# XMC4300 register map
Vendor: Infineon; File version: 0.5.1 (Superset device XMC4800)
CPU: CM4 r2p0, little endian, MPU, FPU, 6 interrupt priority bits
Registers are 32-bit, read-write, reset 0x0 unless marked. A register's access mark holds for its fields unless they carry their own. Offsets are from the block's base; [hi:lo] are bit positions; {n}, {i} and the like mark numbered series; 'fields as' and 'values as' point back to an identical list.

## FLASH0 — Flash Memory Controller
Base 0x58001000
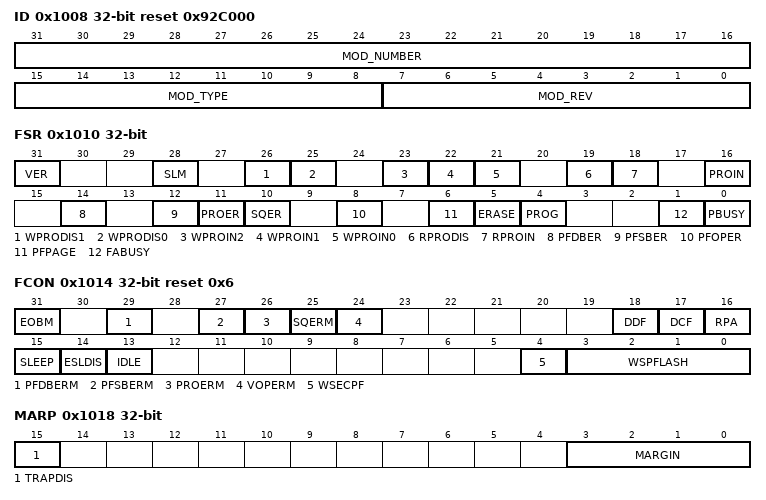
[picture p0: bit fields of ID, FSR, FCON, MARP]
0x1008 ID ro reset 0x92C000 (reset mask 0xFFFFFF00) — Flash Module Identification Register
  [31:16] MOD_NUMBER — Module Number Value
  [15:8] MOD_TYPE — Module Type
  [7:0] MOD_REV — Module Revision Number
0x1010 FSR ro — Flash Status Register
  [31] VER — Verify Error
    0=The page is correctly programmed or the sector correctly erased. All programmed or erased bits have full expected quality.; 1=A program verify error or an erase verify error has been detected. Full quality (retention time) of all programmed ("1") or erased ("0") bits cannot be guaranteed.
  [28] SLM — Flash Sleep Mode
    0=Flash not in sleep mode; 1=Flash is in sleep or shut down mode
  [26] WPRODIS1 — Sector Write Protection Disabled for User 1
    0=All protected sectors of user 1 are locked if write protection is installed; 1=All write-protected sectors of user 1 are temporarily unlocked, if not coincidently locked by user 0 or user 2 or via read protection
  [25] WPRODIS0 — Sector Write Protection Disabled for User 0
    0=All protected sectors of user 0 are locked if write protection is installed; 1=All write-protected sectors of user 0 are temporarily unlocked, if not coincidently locked by user 2 or via read protection
  [23] WPROIN2 — Sector OTP Protection Installed for User 2
    0=No OTP write protection installed for user 2; 1=Sector OTP write protection with ROM functionality is configured and correctly confirmed in the UCB2. The protection is locked for ever.
  [22] WPROIN1 — Sector Write Protection Installed for User 1
    0=No write protection installed for user 1; 1=Sector write protection for user 1 is configured and correctly confirmed in the User Configuration Block 1
  [21] WPROIN0 — Sector Write Protection Installed for User 0
    0=No write protection installed for user 0; 1=Sector write protection for user 0 is configured and correctly confirmed in the User Configuration Block 0
  [19] RPRODIS — Read Protection Disable State
    0=Read protection (if installed) is not disabled; 1=Read and global write protection is temporarily disabled
  [18] RPROIN — Read Protection Installed
    0=No read protection installed; 1=Read protection and global write protection is configured and correctly confirmed in the User Configuration Block 0
  [16] PROIN — Protection Installed
    0=No protection is installed; 1=Read or/and write protection for one or more users is configured and correctly confirmed in the User Configuration Block(s)
  [14] PFDBER — PFLASH Double-Bit Error
    0=No Double-Bit Error detected during read access to PFLASH; 1=Double-Bit Error detected in PFLASH
  [12] PFSBER — PFLASH Single-Bit Error and Correction
    0=No Single-Bit Error detected during read access to PFLASH; 1=Single-Bit Error detected and corrected
  [11] PROER — Protection Error
    0=No protection error; 1=Protection error
  [10] SQER — Command Sequence Error
    0=No sequence error; 1=Command state machine operation unsuccessful because of improper address or command sequence
  [8] PFOPER — Program Flash Operation Error
    0=No operation error reported by Program Flash; 1=Flash array operation aborted, because of a Flash array failure, e.g. an ECC error in microcode.
  [6] PFPAGE — Program Flash in Page Mode
    0=Program Flash not in page mode; 1=Program Flash in page mode; assembly buffer of PFLASH (256 byte) is in use (being filled up)
  [5] ERASE — Erase State
    0=There is no erase operation requested or in progress or just finished; 1=Erase operation requested (from FIM) or in action or finished
  [4] PROG — Programming State
    0=There is no program operation requested or in progress or just finished; 1=Programming operation (write page) requested (from FIM) or in action or finished
  [1] FABUSY — Flash Array Busy
  [0] PBUSY — Program Flash Busy
    0=PFLASH ready, not busy; PFLASH in read mode; 1=PFLASH busy; PFLASH not in read mode
0x1014 FCON access per field reset 0x6 (reset mask 0xFFF0FFFF) — Flash Configuration Register
  [31] EOBM rw — End of Busy Interrupt Mask
    0=Interrupt not enabled; 1=EOB interrupt is enabled
  [29] PFDBERM rw — PFLASH Double-Bit Error Interrupt Mask
    0=Double-Bit Error interrupt for PFLASH not enabled; 1=Double-Bit Error interrupt for PFLASH enabled. Especially intended for margin check
  [27] PFSBERM rw — PFLASH Single-Bit Error Interrupt Mask
    0=No Single-Bit Error interrupt enabled; 1=Single-Bit Error interrupt enabled for PFLASH
  [26] PROERM rw — Protection Error Interrupt Mask
    0=Interrupt not enabled; 1=Flash interrupt because of Protection Error is enabled
  [25] SQERM rw — Command Sequence Error Interrupt Mask
    0=Interrupt not enabled; 1=Flash interrupt because of Sequence Error is enabled
  [24] VOPERM rw — Verify and Operation Error Interrupt Mask
    0=Interrupt not enabled; 1=Flash interrupt because of Verify Error or Operation Error in Flash array (FSI) is enabled
  [18] DDF rw — Disable Any Data Fetch from Flash
    0=Data read access to the Flash memory area is allowed; 1=Data read access to the Flash memory area is not allowed. This bit is not taken into account while RPA='0'.
  [17] DCF rw — Disable Code Fetch from Flash Memory
    0=Code fetching from the Flash memory area is allowed; 1=Code fetching from the Flash memory area is not allowed. This bit is not taken into account while RPA='0'.
  [16] RPA ro — Read Protection Activated
    0=The Flash-internal read protection is not activated. Bits DCF, DDF are not taken into account. Bits DCF, DDFx can be cleared; 1=The Flash-internal read protection is activated. Bits DCF, DDF are enabled and evaluated.
  [15] SLEEP rw — Flash SLEEP
    0=Normal state or wake-up; 1=Flash sleep mode is requested
  [14] ESLDIS rw — External Sleep Request Disable
    0=External sleep request signal input is enabled; 1=Externally requested Flash sleep is disabled
  [13] IDLE rw — Dynamic Flash Idle
    0=Normal/standard Flash read operation; 1=Dynamic idle of Program Flash enabled for power saving; static prefetching disabled
  [4] WSECPF rw — Wait State for Error Correction of PFLASH
    0=No additional wait state for error correction; 1=One additional wait state for error correction during read access to Program Flash. If enabled, this wait state is only used for the first transfer of a burst transfer.
  [3:0] WSPFLASH rw — Wait States for read access to PFLASH
    0=PFLASH access in one clock cycle; 1=PFLASH access in one clock cycle; 2=PFLASH access in two clock cycles; 3=PFLASH access in three clock cycles; 15=PFLASH access in fifteen clock cycles
0x1018 MARP — Margin Control Register PFLASH
  [15] TRAPDIS — PFLASH Double-Bit Error Trap Disable
    0=If a double-bit error occurs in PFLASH, a bus error trap is generated; 1=The double-bit error trap is disabled. Shall be used only during margin check
  [3:0] MARGIN — PFLASH Margin Selection
    0=Standard (default) margin; 1=Tight margin for 0 (low) level. Suboptimal 0-bits are read as 1s.; 4=Tight margin for 1 (high) level. Suboptimal 1-bits are read as 0s.
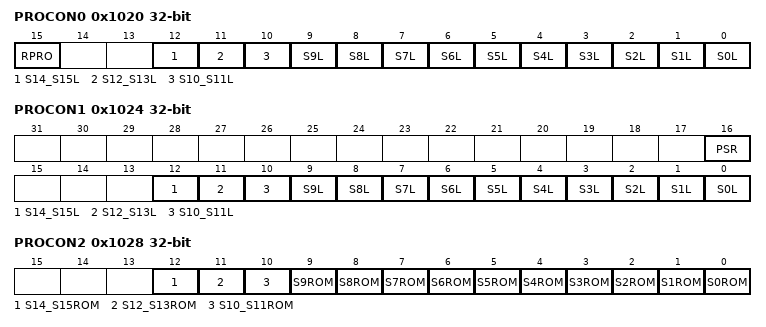
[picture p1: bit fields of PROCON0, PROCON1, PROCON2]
0x1020 PROCON0 ro (reset mask 0xFFFF0000) — Flash Protection Configuration Register User 0
  [15] RPRO — Read Protection Configuration
    0=No read protection configured; 1=Read protection and global write protection is configured by user 0 (master user)
  [12] S14_S15L — Sectors 14 and 15 Locked for Write Protection by User 0
    0=No write protection is configured for sectors 14+15; 1=Write protection is configured for sectors 14+15
  [11] S12_S13L — Sectors 12 and 13 Locked for Write Protection by User 0
    0=No write protection is configured for sectors 12+13; 1=Write protection is configured for sectors 12+13
  [10] S10_S11L — Sectors 10 and 11 Locked for Write Protection by User 0
    0=No write protection is configured for sectors 10+11; 1=Write protection is configured for sectors 10+11
  [n] S{n}L (n=0..9) — Sector {n} Locked for Write Protection by User 0
    0=No write protection is configured for sector n; 1=Write protection is configured for sector n
0x1024 PROCON1 ro (reset mask 0xFFFF0000) — Flash Protection Configuration Register User 1
  [16] PSR — Physical Sector Repair
    0=Physical Sector Repair command disabled; Erase Physical Sector command sequence available; 1=Physical Sector Repair command sequence enabled; Erase Physical Sector command sequence disabled
  [12] S14_S15L — Sectors 14 and 15 Locked for Write Protection by User 1
    values as PROCON0.S14_S15L
  [11] S12_S13L — Sectors 12 and 13 Locked for Write Protection by User 1
    values as PROCON0.S12_S13L
  [10] S10_S11L — Sectors 10 and 11 Locked for Write Protection by User 1
    values as PROCON0.S10_S11L
  [n] S{n}L (n=0..9) — Sector {n} Locked for Write Protection by User 1
    values as PROCON0.S0L
0x1028 PROCON2 ro (reset mask 0xFFFF0000) — Flash Protection Configuration Register User 2
  [12] S14_S15ROM — Sectors 14 and 15 Locked Forever by User 2
    0=No ROM functionality is configured for sectors 14+15; 1=ROM functionality is configured for sectors 14+15
  [11] S12_S13ROM — Sectors 12 and 13 Locked Forever by User 2
    0=No ROM functionality is configured for sectors 12+13; 1=ROM functionality is configured for sectors 12+13
  [10] S10_S11ROM — Sectors 10 and 11 Locked Forever by User 2
    0=No ROM functionality is configured for sectors 10+11; 1=ROM functionality is configured for sectors 10+11
  [n] S{n}ROM (n=0..9) — Sector {n} Locked Forever by User 2
    0=No ROM functionality configured for sector n; 1=ROM functionality is configured for sector n. Re-programming of this sector is no longer possible.
